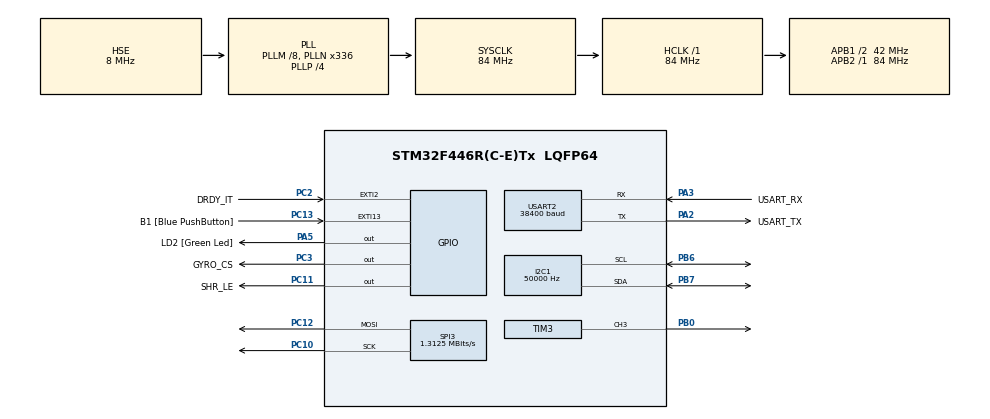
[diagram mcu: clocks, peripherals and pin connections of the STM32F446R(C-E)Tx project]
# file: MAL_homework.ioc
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Dma.Request0=SPI3_TX
Dma.Request1=USART2_RX
Dma.SPI3_TX.0.Direction=DMA_MEMORY_TO_PERIPH
Dma.SPI3_TX.0.FIFOMode=DMA_FIFOMODE_DISABLE
Dma.SPI3_TX.0.Instance=DMA1_Stream7
Dma.SPI3_TX.0.MemDataAlignment=DMA_MDATAALIGN_BYTE
Dma.SPI3_TX.0.MemInc=DMA_MINC_ENABLE
Dma.SPI3_TX.0.Mode=DMA_NORMAL
Dma.SPI3_TX.0.PeriphDataAlignment=DMA_PDATAALIGN_BYTE
Dma.SPI3_TX.0.PeriphInc=DMA_PINC_DISABLE
Dma.SPI3_TX.0.Priority=DMA_PRIORITY_LOW
Dma.USART2_RX.1.Direction=DMA_PERIPH_TO_MEMORY
Dma.USART2_RX.1.FIFOMode=DMA_FIFOMODE_DISABLE
Dma.USART2_RX.1.Instance=DMA1_Stream5
Dma.USART2_RX.1.MemDataAlignment=DMA_MDATAALIGN_BYTE
Dma.USART2_RX.1.MemInc=DMA_MINC_ENABLE
Dma.USART2_RX.1.Mode=DMA_CIRCULAR
Dma.USART2_RX.1.PeriphDataAlignment=DMA_PDATAALIGN_BYTE
Dma.USART2_RX.1.PeriphInc=DMA_PINC_DISABLE
Dma.USART2_RX.1.Priority=DMA_PRIORITY_MEDIUM
I2C1.AddressingMode=I2C_ADDRESSINGMODE_7BIT
I2C1.ClockSpeed=50000
I2C1.DualAddressMode=I2C_DUALADDRESS_DISABLE
I2C1.DutyCycle=I2C_DUTYCYCLE_2
I2C1.GeneralCallMode=I2C_GENERALCALL_DISABLE
I2C1.I2C_Mode=I2C_Fast
I2C1.NoStretchMode=I2C_NOSTRETCH_ENABLE
Mcu.Family=STM32F4
Mcu.Name=STM32F446R(C-E)Tx
Mcu.Package=LQFP64
NVIC.DMA1_Stream5_IRQn=true\:0\:0\:false\:false\:true\:false\:true\:true
NVIC.DMA1_Stream7_IRQn=true\:0\:0\:false\:false\:true\:false\:true\:true
NVIC.EXTI2_IRQn=true\:0\:0\:false\:false\:true\:true\:true\:true
NVIC.PriorityGroup=NVIC_PRIORITYGROUP_0
NVIC.SPI3_IRQn=true\:0\:0\:false\:false\:true\:true\:true\:true
NVIC.TIM2_IRQn=true\:0\:0\:false\:false\:true\:true\:true\:true
PA13.GPIO_Label=TMS
PA13.Mode=Serial_Wire
PA13.Signal=SYS_JTMS-SWDIO
PA14.GPIO_Label=TCK
PA14.Mode=Serial_Wire
PA14.Signal=SYS_JTCK-SWCLK
PA2.GPIO_Label=USART_TX
PA2.Mode=Asynchronous
PA2.Signal=USART2_TX
PA3.GPIO_Label=USART_RX
PA3.Mode=Asynchronous
PA3.Signal=USART2_RX
PA5.GPIO_Label=LD2 [Green Led]
PA5.Signal=GPIO_Output
PB0.Signal=S_TIM3_CH3
PB3.GPIO_Label=SWO
PB3.Signal=SYS_JTDO-SWO
PB6.GPIO_Pu=GPIO_PULLUP
PB6.GPIO_Speed=GPIO_SPEED_FREQ_HIGH
PB6.Mode=I2C
PB6.Signal=I2C1_SCL
PB7.GPIO_Pu=GPIO_PULLUP
PB7.GPIO_Speed=GPIO_SPEED_FREQ_HIGH
PB7.Mode=I2C
PB7.Signal=I2C1_SDA
PC10.Mode=TX_Only_Simplex_Unidirect_Master
PC10.Signal=SPI3_SCK
PC11.GPIO_Label=SHR_LE
PC11.Signal=GPIO_Output
PC12.Mode=TX_Only_Simplex_Unidirect_Master
PC12.Signal=SPI3_MOSI
PC13.GPIO_Label=B1 [Blue PushButton]
PC13.GPIO_ModeDefaultEXTI=GPIO_MODE_IT_FALLING
PC13.Signal=GPXTI13
PC14-OSC32_IN.Mode=LSE-External-Oscillator
PC14-OSC32_IN.Signal=RCC_OSC32_IN
PC15-OSC32_OUT.Mode=LSE-External-Oscillator
PC15-OSC32_OUT.Signal=RCC_OSC32_OUT
PC2.GPIO_Label=DRDY_IT
PC2.GPIO_ModeDefaultEXTI=GPIO_MODE_IT_RISING
PC2.Signal=GPXTI2
PC3.GPIO_Label=GYRO_CS
PC3.Signal=GPIO_Output
PH0-OSC_IN.Mode=HSE-External-Oscillator
PH0-OSC_IN.Signal=RCC_OSC_IN
PH1-OSC_OUT.Mode=HSE-External-Oscillator
PH1-OSC_OUT.Signal=RCC_OSC_OUT
ProjectManager.HeapSize=0x200
ProjectManager.StackSize=0x400
ProjectManager.TargetToolchain=STM32CubeIDE
RCC.48MHZClocksFreq_Value=84000000
RCC.AHBFreq_Value=84000000
RCC.APB1CLKDivider=RCC_HCLK_DIV2
RCC.APB1Freq_Value=42000000
RCC.APB1TimFreq_Value=84000000
RCC.APB2Freq_Value=84000000
RCC.APB2TimFreq_Value=84000000
RCC.CortexFreq_Value=84000000
RCC.FLatency-AdvancedSettings=FLASH_LATENCY_2
RCC.HCLKFreq_Value=84000000
RCC.HSE_VALUE=8000000
RCC.HSI_VALUE=16000000
RCC.PLLM=8
RCC.PLLN=336
RCC.PLLP=RCC_PLLP_DIV4
RCC.PLLSourceVirtual=RCC_PLLSOURCE_HSE
RCC.SYSCLKFreq_VALUE=84000000
RCC.SYSCLKSource=RCC_SYSCLKSOURCE_PLLCLK
RCC.USBFreq_Value=168000000
RCC.VCOOutputFreq_Value=336000000
SH.S_TIM3_CH3.0=TIM3_CH3,PWM Generation3 CH3
SPI3.BaudRatePrescaler=SPI_BAUDRATEPRESCALER_32
SPI3.CalculateBaudRate=1.3125 MBits/s
SPI3.DataSize=SPI_DATASIZE_8BIT
SPI3.Direction=SPI_DIRECTION_2LINES
SPI3.Mode=SPI_MODE_MASTER
SPI3.VirtualType=VM_MASTER
TIM2.Period=5000-1
TIM2.Prescaler=84-1
TIM3.Channel-PWM\ Generation3\ CH3=TIM_CHANNEL_3
TIM3.Period=255
TIM3.Prescaler=16
TIM3.Pulse-PWM\ Generation3\ CH3=200
USART2.BaudRate=38400
USART2.VirtualMode=VM_ASYNC
VP_TIM2_VS_ClockSourceINT.Mode=Internal
VP_TIM3_VS_ClockSourceINT.Mode=Internal
board=NUCLEO-F446RE

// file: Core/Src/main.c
/* USER CODE BEGIN Header */
/**
  ******************************************************************************
  * @file           : main.c
  * @brief          : Main program body
  ******************************************************************************
  * @attention
  *
  * Copyright (c) 2023 STMicroelectronics.
  * All rights reserved.
  *
  * This software is licensed under terms that can be found in the LICENSE file
  * in the root directory of this software component.
  * If no LICENSE file comes with this software, it is provided AS-IS.
  *
  ******************************************************************************
  */
/* USER CODE END Header */
#include "main.h"
#include "dma.h"
#include "i2c.h"
#include "spi.h"
#include "tim.h"
#include "usart.h"
#include "gpio.h"

/* USER CODE BEGIN Includes */
#include "program.h"
/* USER CODE END Includes */

void SystemClock_Config(void);

int main(void)
{

  /* MCU Configuration--------------------------------------------------------*/

  /* Reset of all peripherals, Initializes the Flash interface and the Systick. */
  HAL_Init();

  /* Configure the system clock */
  SystemClock_Config();

  /* Initialize all configured peripherals */
  MX_GPIO_Init();
  MX_DMA_Init();
  MX_I2C1_Init();
  MX_SPI3_Init();
  MX_USART2_UART_Init();
  MX_TIM3_Init();
  MX_TIM2_Init();
  /* USER CODE BEGIN 2 */
    init();
  /* USER CODE END 2 */

  /* Infinite loop */
  /* USER CODE BEGIN WHILE */
  while (1)
  {
      loop();
    /* USER CODE END WHILE */

  }
}

void SystemClock_Config(void)
{
  RCC_OscInitTypeDef RCC_OscInitStruct = {0};
  RCC_ClkInitTypeDef RCC_ClkInitStruct = {0};

  /** Configure the main internal regulator output voltage
  */
  __HAL_RCC_PWR_CLK_ENABLE();
  __HAL_PWR_VOLTAGESCALING_CONFIG(PWR_REGULATOR_VOLTAGE_SCALE3);

  /** Initializes the RCC Oscillators according to the specified parameters
  * in the RCC_OscInitTypeDef structure.
  */
  RCC_OscInitStruct.OscillatorType = RCC_OSCILLATORTYPE_HSE;
  RCC_OscInitStruct.HSEState = RCC_HSE_ON;
  RCC_OscInitStruct.PLL.PLLState = RCC_PLL_ON;
  RCC_OscInitStruct.PLL.PLLSource = RCC_PLLSOURCE_HSE;
  RCC_OscInitStruct.PLL.PLLM = 8;
  RCC_OscInitStruct.PLL.PLLN = 336;
  RCC_OscInitStruct.PLL.PLLP = RCC_PLLP_DIV4;
  RCC_OscInitStruct.PLL.PLLQ = 2;
  RCC_OscInitStruct.PLL.PLLR = 2;
  if (HAL_RCC_OscConfig(&RCC_OscInitStruct) != HAL_OK)
  {
    Error_Handler();
  }

  /** Initializes the CPU, AHB and APB buses clocks
  */
  RCC_ClkInitStruct.ClockType = RCC_CLOCKTYPE_HCLK|RCC_CLOCKTYPE_SYSCLK
                              |RCC_CLOCKTYPE_PCLK1|RCC_CLOCKTYPE_PCLK2;
  RCC_ClkInitStruct.SYSCLKSource = RCC_SYSCLKSOURCE_PLLCLK;
  RCC_ClkInitStruct.AHBCLKDivider = RCC_SYSCLK_DIV1;
  RCC_ClkInitStruct.APB1CLKDivider = RCC_HCLK_DIV2;
  RCC_ClkInitStruct.APB2CLKDivider = RCC_HCLK_DIV1;

  if (HAL_RCC_ClockConfig(&RCC_ClkInitStruct, FLASH_LATENCY_2) != HAL_OK)
  {
    Error_Handler();
  }
}

void Error_Handler(void)
{
  __disable_irq();
  while (1)
  {
  }
}
